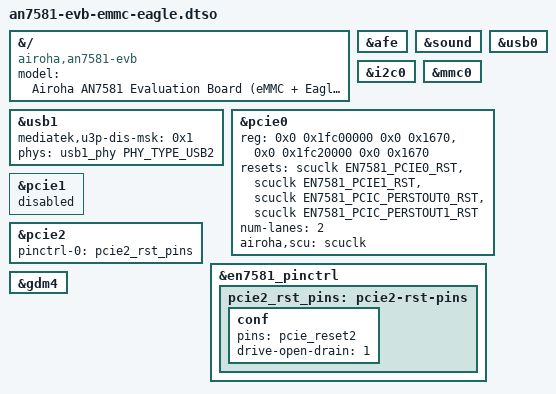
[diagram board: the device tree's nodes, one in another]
// SPDX-License-Identifier: (GPL-2.0-only OR BSD-2-Clause)
/dts-v1/;
/plugin/;

#include <dt-bindings/phy/phy.h>
#include <dt-bindings/reset/airoha,en7581-reset.h>
#include "an7581-npu-mt7996.dtsi"

&{/} {
	model = "Airoha AN7581 Evaluation Board (eMMC + Eagle)";
	compatible = "airoha,an7581-evb", "airoha,an7581", "airoha,en7581";
};

&afe {
	status = "okay";
};

&sound {
	status = "okay";
};

&usb0 {
	status = "okay";
};

&usb1 {
	status = "okay";

	mediatek,u3p-dis-msk = <0x1>;
	phys = <&usb1_phy PHY_TYPE_USB2>;
};

&i2c0 {
	status = "okay";
};

&mmc0 {
	status = "okay";
};

&pcie0 {
	reg = <0x0 0x1fc00000 0x0 0x1670>,
	      <0x0 0x1fc20000 0x0 0x1670>;
	reg-names = "pcie-mac", "sec-pcie-mac";

	resets = <&scuclk EN7581_PCIE0_RST>,
		 <&scuclk EN7581_PCIE1_RST>,
		 <&scuclk EN7581_PCIC_PERSTOUT0_RST>,
		 <&scuclk EN7581_PCIC_PERSTOUT1_RST>;
	reset-names = "phy-lane0", "phy-lane1",
		      "perstout", "sec-perstout";

	num-lanes = <2>;

	airoha,scu = <&scuclk>;
};

&pcie1 {
	status = "disabled";
};

&pcie2 {
	pinctrl-names = "default";
	pinctrl-0 = <&pcie2_rst_pins>;
	status = "okay";
};

&en7581_pinctrl {
	pcie2_rst_pins: pcie2-rst-pins {
		conf {
			pins = "pcie_reset2";
			drive-open-drain = <1>;
		};
	};
};

&gdm4 {
	status = "okay";
};
